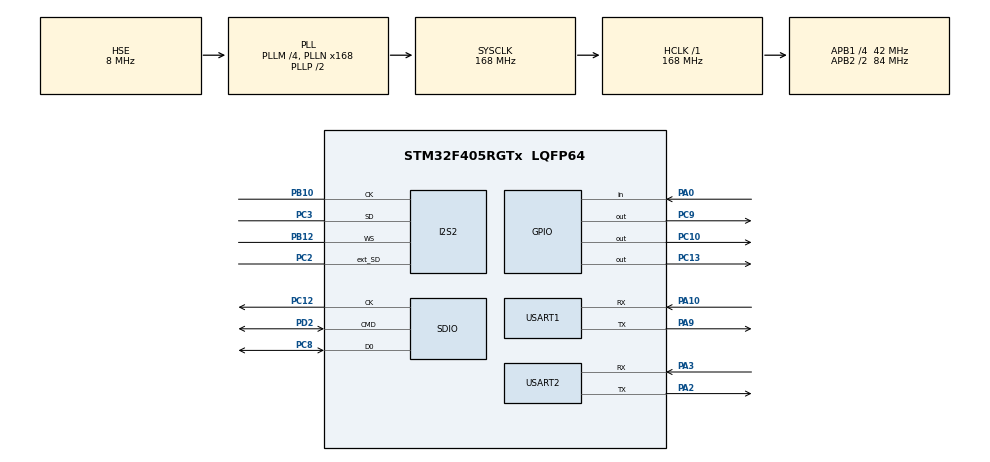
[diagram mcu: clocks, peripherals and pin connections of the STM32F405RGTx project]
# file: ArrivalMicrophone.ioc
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Mcu.Family=STM32F4
PC3.Mode=Full_Duplex_Master
Dma.SPI2_RX.0.Instance=DMA1_Stream3
PH0-OSC_IN.Signal=RCC_OSC_IN
RCC.CortexFreq_Value=168000000
Dma.SDIO_RX.1.PeriphDataAlignment=DMA_PDATAALIGN_WORD
PB10.GPIO_Speed=GPIO_SPEED_FREQ_VERY_HIGH
PB10.Mode=Full_Duplex_Master
VP_FATFS_VS_SDIO.Mode=SDIO
PA10.GPIO_PuPd=GPIO_PULLUP
PC10.Signal=GPIO_Output
PC12.Signal=SDIO_CK
Dma.SDIO_RX.1.Mode=DMA_PFCTRL
PA3.GPIO_PuPd=GPIO_PULLUP
Dma.SDIO_RX.1.Direction=DMA_PERIPH_TO_MEMORY
Dma.SDIO_RX.1.Priority=DMA_PRIORITY_LOW
FREERTOS.configTICK_RATE_HZ=100
PC2.GPIO_Speed=GPIO_SPEED_FREQ_VERY_HIGH
PC3.GPIO_Speed=GPIO_SPEED_FREQ_VERY_HIGH
RCC.SYSCLKSource=RCC_SYSCLKSOURCE_PLLCLK
ProjectManager.StackSize=0x400
VP_FREERTOS_VS_CMSIS_V2.Mode=CMSIS_V2
Dma.SDIO_RX.1.Instance=DMA2_Stream3
Dma.SDIO_TX.2.Mode=DMA_PFCTRL
Dma.SDIO_TX.2.MemDataAlignment=DMA_MDATAALIGN_WORD
RCC.HCLKFreq_Value=168000000
RCC.APB2TimFreq_Value=168000000
Dma.SDIO_RX.1.FIFOMode=DMA_FIFOMODE_ENABLE
FATFS._MULTI_PARTITION=1
PC3.Signal=I2S2_SD
RCC.AHBFreq_Value=168000000
PH0-OSC_IN.Mode=HSE-External-Oscillator
RCC.HSE_VALUE=8000000
PC13-ANTI_TAMP.Signal=GPIO_Output
VP_SYS_VS_tim1.Mode=TIM1
Dma.SDIO_TX.2.Direction=DMA_MEMORY_TO_PERIPH
Dma.SPI2_RX.0.MemDataAlignment=DMA_MDATAALIGN_HALFWORD
I2S2.DataFormat=I2S_DATAFORMAT_24B
PC10.PinState=GPIO_PIN_SET
Dma.SPI2_RX.0.MemInc=DMA_MINC_ENABLE
PH1-OSC_OUT.Mode=HSE-External-Oscillator
Mcu.Package=LQFP64
PB12.Mode=Full_Duplex_Master
NVIC.TimeBase=TIM1_UP_TIM10_IRQn
USART2.VirtualMode=VM_ASYNC
Dma.SDIO_TX.2.PeriphBurst=DMA_PBURST_INC4
I2S2.Mode=I2S_MODE_MASTER_RX
NVIC.TimeBaseIP=TIM1
PA10.Signal=USART1_RX
Dma.SDIO_RX.1.PeriphBurst=DMA_PBURST_INC4
RCC.APB2CLKDivider=RCC_HCLK_DIV2
Dma.Request2=SDIO_TX
Dma.Request1=SDIO_RX
RCC.APB1TimFreq_Value=84000000
Dma.SPI2_RX.0.Direction=DMA_PERIPH_TO_MEMORY
Dma.Request0=SPI2_RX
Dma.SDIO_TX.2.FIFOThreshold=DMA_FIFO_THRESHOLD_FULL
PA3.Signal=USART2_RX
RCC.PLLSourceVirtual=RCC_PLLSOURCE_HSE
Dma.SDIO_TX.2.MemInc=DMA_MINC_ENABLE
I2S2.AudioFreq=I2S_AUDIOFREQ_16K
FREERTOS.Tasks01=mainTask,24,1024,mainTask_main,Default,&mainTask,Static,defaultTaskBuffer,defaultTaskControlBlock
I2S2.Instance=SPI$Index
PA10.Mode=Asynchronous
Dma.SPI2_RX.0.Mode=DMA_CIRCULAR
PC8.Signal=SDIO_D0
PC2.Signal=I2S2_ext_SD
PC9.PinState=GPIO_PIN_SET
PC2.Mode=Full_Duplex_Master
Dma.SDIO_TX.2.Instance=DMA2_Stream6
RCC.APB1CLKDivider=RCC_HCLK_DIV4
NVIC.USART2_IRQn=true\:0\:0\:false\:false\:true\:true\:true\:true
NVIC.SDIO_IRQn=true\:0\:0\:false\:false\:true\:false\:true\:true
PC13-ANTI_TAMP.PinState=GPIO_PIN_SET
PA0-WKUP.Signal=GPIO_Input
Dma.SDIO_RX.1.PeriphInc=DMA_PINC_DISABLE
PA3.Mode=Asynchronous
PA9.Mode=Asynchronous
Dma.SPI2_RX.0.PeriphDataAlignment=DMA_PDATAALIGN_HALFWORD
ProjectManager.TargetToolchain=Makefile
PA9.Signal=USART1_TX
I2S2.VirtualMode=I2S_MODE_MASTER
Dma.SDIO_TX.2.PeriphDataAlignment=DMA_PDATAALIGN_WORD
SDIO.ClockDiv=3
NVIC.DMA2_Stream3_IRQn=true\:0\:0\:false\:false\:true\:true\:false\:true
NVIC.DMA2_Stream6_IRQn=true\:0\:0\:false\:false\:true\:true\:false\:true
RCC.LSE_VALUE=32768
PB12.GPIO_Speed=GPIO_SPEED_FREQ_VERY_HIGH
Dma.SDIO_RX.1.MemDataAlignment=DMA_MDATAALIGN_WORD
PB10.Signal=I2S2_CK
Dma.SDIO_RX.1.FIFOThreshold=DMA_FIFO_THRESHOLD_FULL
PD2.Mode=SD_1_bit
PC12.Mode=SD_1_bit
board=custom
Dma.SDIO_RX.1.MemBurst=DMA_MBURST_INC4
RCC.VCOOutputFreq_Value=336000000
RCC.APB2Freq_Value=84000000
PH1-OSC_OUT.Signal=RCC_OSC_OUT
Dma.SPI2_RX.0.FIFOMode=DMA_FIFOMODE_DISABLE
PC2.GPIO_PuPd=GPIO_PULLUP
Dma.SPI2_RX.0.Priority=DMA_PRIORITY_HIGH
Mcu.Name=STM32F405RGTx
PA2.Signal=USART2_TX
Dma.SDIO_TX.2.Priority=DMA_PRIORITY_LOW
FATFS._MAX_SS=4096
I2S2.FullDuplexMode=I2S_FULLDUPLEXMODE_ENABLE
PC8.Mode=SD_1_bit
RCC.48MHZClocksFreq_Value=48000000
RCC.SYSCLKFreq_VALUE=168000000
I2S2.ErrorAudioFreq=-0.26 %
Dma.SPI2_RX.0.PeriphInc=DMA_PINC_DISABLE
USART1.VirtualMode=VM_ASYNC
Dma.SDIO_TX.2.MemBurst=DMA_MBURST_INC4
ProjectManager.HeapSize=0x200
Dma.SDIO_RX.1.MemInc=DMA_MINC_ENABLE
Dma.SDIO_TX.2.FIFOMode=DMA_FIFOMODE_ENABLE
NVIC.TIM1_UP_TIM10_IRQn=true\:0\:0\:false\:false\:true\:false\:true\:true
RCC.HSI_VALUE=16000000
RCC.PLLQ=7
NVIC.PriorityGroup=NVIC_PRIORITYGROUP_4
RCC.PLLM=4
RCC.PLLN=168
PA2.Mode=Asynchronous
Dma.SDIO_TX.2.PeriphInc=DMA_PINC_DISABLE
PA0-WKUP.GPIO_PuPd=GPIO_PULLUP
NVIC.DMA1_Stream3_IRQn=true\:0\:0\:false\:false\:true\:true\:false\:true
PC9.Signal=GPIO_Output
PD2.Signal=SDIO_CMD
RCC.APB1Freq_Value=42000000
I2S2.RealAudioFreq=15.957 KHz
PB12.Signal=I2S2_WS
PC3.GPIO_PuPd=GPIO_PULLUP

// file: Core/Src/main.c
/* USER CODE BEGIN Header */
/**
  ******************************************************************************
  * @file           : main.c
  * @brief          : Main program body
  ******************************************************************************
  * @attention
  *
  * <h2><center>&copy; Copyright (c) 2020 STMicroelectronics.
  * All rights reserved.</center></h2>
  *
  * This software component is licensed by ST under Ultimate Liberty license
  * SLA0044, the "License"; You may not use this file except in compliance with
  * the License. You may obtain a copy of the License at:
  *                             www.st.com/SLA0044
  *
  ******************************************************************************
  */
/* USER CODE END Header */
#include "main.h"
#include "cmsis_os.h"
#include "fatfs.h"

/* USER CODE BEGIN Includes */
#include "../../src/maintask.h"
#include "../../src/led.h"
/* USER CODE END Includes */

typedef StaticTask_t osStaticThreadDef_t;

I2S_HandleTypeDef hi2s2;
DMA_HandleTypeDef hdma_spi2_rx;

SD_HandleTypeDef hsd;
DMA_HandleTypeDef hdma_sdio_rx;
DMA_HandleTypeDef hdma_sdio_tx;

UART_HandleTypeDef huart1;
UART_HandleTypeDef huart2;

/* Definitions for mainTask */
osThreadId_t mainTaskHandle;
uint32_t defaultTaskBuffer[ 1024 ];
osStaticThreadDef_t defaultTaskControlBlock;
const osThreadAttr_t mainTask_attributes = {
  .name = "mainTask",
  .stack_mem = &defaultTaskBuffer[0],
  .stack_size = sizeof(defaultTaskBuffer),
  .cb_mem = &defaultTaskControlBlock,
  .cb_size = sizeof(defaultTaskControlBlock),
  .priority = (osPriority_t) osPriorityNormal,
};

void SystemClock_Config(void);
static void MX_GPIO_Init(void);
static void MX_DMA_Init(void);
static void MX_I2S2_Init(void);
static void MX_SDIO_SD_Init(void);
static void MX_USART1_UART_Init(void);
static void MX_USART2_UART_Init(void);
void mainTask_main(void *argument);

int main(void)
{

  /* MCU Configuration--------------------------------------------------------*/

  /* Reset of all peripherals, Initializes the Flash interface and the Systick. */
  HAL_Init();

  /* Configure the system clock */
  SystemClock_Config();

  /* Initialize all configured peripherals */
  MX_GPIO_Init();
  MX_DMA_Init();
  MX_I2S2_Init();
  MX_SDIO_SD_Init();
  MX_USART1_UART_Init();
  MX_USART2_UART_Init();
  MX_FATFS_Init();

  /* Init scheduler */
  osKernelInitialize();

  /* Create the thread(s) */
  /* creation of mainTask */
  mainTaskHandle = osThreadNew(mainTask_main, (void*) &mainTask, &mainTask_attributes);

  /* Start scheduler */
  osKernelStart();

  /* We should never get here as control is now taken by the scheduler */
  /* Infinite loop */
  while (1)
  {

  }
}

void SystemClock_Config(void)
{
  RCC_OscInitTypeDef RCC_OscInitStruct = {0};
  RCC_ClkInitTypeDef RCC_ClkInitStruct = {0};
  RCC_PeriphCLKInitTypeDef PeriphClkInitStruct = {0};

  /** Configure the main internal regulator output voltage
  */
  __HAL_RCC_PWR_CLK_ENABLE();
  __HAL_PWR_VOLTAGESCALING_CONFIG(PWR_REGULATOR_VOLTAGE_SCALE1);
  /** Initializes the RCC Oscillators according to the specified parameters
  * in the RCC_OscInitTypeDef structure.
  */
  RCC_OscInitStruct.OscillatorType = RCC_OSCILLATORTYPE_HSE;
  RCC_OscInitStruct.HSEState = RCC_HSE_ON;
  RCC_OscInitStruct.PLL.PLLState = RCC_PLL_ON;
  RCC_OscInitStruct.PLL.PLLSource = RCC_PLLSOURCE_HSE;
  RCC_OscInitStruct.PLL.PLLM = 4;
  RCC_OscInitStruct.PLL.PLLN = 168;
  RCC_OscInitStruct.PLL.PLLP = RCC_PLLP_DIV2;
  RCC_OscInitStruct.PLL.PLLQ = 7;
  if (HAL_RCC_OscConfig(&RCC_OscInitStruct) != HAL_OK)
  {
    Error_Handler();
  }
  /** Initializes the CPU, AHB and APB buses clocks
  */
  RCC_ClkInitStruct.ClockType = RCC_CLOCKTYPE_HCLK|RCC_CLOCKTYPE_SYSCLK
                              |RCC_CLOCKTYPE_PCLK1|RCC_CLOCKTYPE_PCLK2;
  RCC_ClkInitStruct.SYSCLKSource = RCC_SYSCLKSOURCE_PLLCLK;
  RCC_ClkInitStruct.AHBCLKDivider = RCC_SYSCLK_DIV1;
  RCC_ClkInitStruct.APB1CLKDivider = RCC_HCLK_DIV4;
  RCC_ClkInitStruct.APB2CLKDivider = RCC_HCLK_DIV2;

  if (HAL_RCC_ClockConfig(&RCC_ClkInitStruct, FLASH_LATENCY_5) != HAL_OK)
  {
    Error_Handler();
  }
  PeriphClkInitStruct.PeriphClockSelection = RCC_PERIPHCLK_I2S;
  PeriphClkInitStruct.PLLI2S.PLLI2SN = 192;
  PeriphClkInitStruct.PLLI2S.PLLI2SR = 2;
  if (HAL_RCCEx_PeriphCLKConfig(&PeriphClkInitStruct) != HAL_OK)
  {
    Error_Handler();
  }
}

static void MX_I2S2_Init(void)
{

  hi2s2.Instance = SPI2;
  hi2s2.Init.Mode = I2S_MODE_MASTER_RX;
  hi2s2.Init.Standard = I2S_STANDARD_PHILIPS;
  hi2s2.Init.DataFormat = I2S_DATAFORMAT_24B;
  hi2s2.Init.MCLKOutput = I2S_MCLKOUTPUT_DISABLE;
  hi2s2.Init.AudioFreq = I2S_AUDIOFREQ_16K;
  hi2s2.Init.CPOL = I2S_CPOL_LOW;
  hi2s2.Init.ClockSource = I2S_CLOCK_PLL;
  hi2s2.Init.FullDuplexMode = I2S_FULLDUPLEXMODE_ENABLE;
  if (HAL_I2S_Init(&hi2s2) != HAL_OK)
  {
    Error_Handler();
  }

}

static void MX_SDIO_SD_Init(void)
{

  hsd.Instance = SDIO;
  hsd.Init.ClockEdge = SDIO_CLOCK_EDGE_RISING;
  hsd.Init.ClockBypass = SDIO_CLOCK_BYPASS_DISABLE;
  hsd.Init.ClockPowerSave = SDIO_CLOCK_POWER_SAVE_DISABLE;
  hsd.Init.BusWide = SDIO_BUS_WIDE_1B;
  hsd.Init.HardwareFlowControl = SDIO_HARDWARE_FLOW_CONTROL_DISABLE;
  hsd.Init.ClockDiv = 3;

}

static void MX_USART1_UART_Init(void)
{

  huart1.Instance = USART1;
  huart1.Init.BaudRate = 115200;
  huart1.Init.WordLength = UART_WORDLENGTH_8B;
  huart1.Init.StopBits = UART_STOPBITS_1;
  huart1.Init.Parity = UART_PARITY_NONE;
  huart1.Init.Mode = UART_MODE_TX_RX;
  huart1.Init.HwFlowCtl = UART_HWCONTROL_NONE;
  huart1.Init.OverSampling = UART_OVERSAMPLING_16;
  if (HAL_UART_Init(&huart1) != HAL_OK)
  {
    Error_Handler();
  }

}

static void MX_USART2_UART_Init(void)
{

  huart2.Instance = USART2;
  huart2.Init.BaudRate = 115200;
  huart2.Init.WordLength = UART_WORDLENGTH_8B;
  huart2.Init.StopBits = UART_STOPBITS_1;
  huart2.Init.Parity = UART_PARITY_NONE;
  huart2.Init.Mode = UART_MODE_TX_RX;
  huart2.Init.HwFlowCtl = UART_HWCONTROL_NONE;
  huart2.Init.OverSampling = UART_OVERSAMPLING_16;
  if (HAL_UART_Init(&huart2) != HAL_OK)
  {
    Error_Handler();
  }

}

static void MX_DMA_Init(void)
{

  /* DMA controller clock enable */
  __HAL_RCC_DMA1_CLK_ENABLE();
  __HAL_RCC_DMA2_CLK_ENABLE();

  /* DMA interrupt init */
  /* DMA1_Stream3_IRQn interrupt configuration */
  HAL_NVIC_SetPriority(DMA1_Stream3_IRQn, 0, 0);
  HAL_NVIC_EnableIRQ(DMA1_Stream3_IRQn);
  /* DMA2_Stream3_IRQn interrupt configuration */
  HAL_NVIC_SetPriority(DMA2_Stream3_IRQn, 0, 0);
  HAL_NVIC_EnableIRQ(DMA2_Stream3_IRQn);
  /* DMA2_Stream6_IRQn interrupt configuration */
  HAL_NVIC_SetPriority(DMA2_Stream6_IRQn, 0, 0);
  HAL_NVIC_EnableIRQ(DMA2_Stream6_IRQn);

}

static void MX_GPIO_Init(void)
{
  GPIO_InitTypeDef GPIO_InitStruct = {0};

  /* GPIO Ports Clock Enable */
  __HAL_RCC_GPIOC_CLK_ENABLE();
  __HAL_RCC_GPIOH_CLK_ENABLE();
  __HAL_RCC_GPIOA_CLK_ENABLE();
  __HAL_RCC_GPIOB_CLK_ENABLE();
  __HAL_RCC_GPIOD_CLK_ENABLE();

  /*Configure GPIO pin Output Level */
  HAL_GPIO_WritePin(GPIOC, GPIO_PIN_13|GPIO_PIN_9|GPIO_PIN_10, GPIO_PIN_SET);

  /*Configure GPIO pins : PC13 PC9 PC10 */
  GPIO_InitStruct.Pin = GPIO_PIN_13|GPIO_PIN_9|GPIO_PIN_10;
  GPIO_InitStruct.Mode = GPIO_MODE_OUTPUT_PP;
  GPIO_InitStruct.Pull = GPIO_NOPULL;
  GPIO_InitStruct.Speed = GPIO_SPEED_FREQ_LOW;
  HAL_GPIO_Init(GPIOC, &GPIO_InitStruct);

  /*Configure GPIO pin : PA0 */
  GPIO_InitStruct.Pin = GPIO_PIN_0;
  GPIO_InitStruct.Mode = GPIO_MODE_INPUT;
  GPIO_InitStruct.Pull = GPIO_PULLUP;
  HAL_GPIO_Init(GPIOA, &GPIO_InitStruct);

}

/* USER CODE BEGIN 4 */
#define mainTask_main mainTask_main_unused
/* USER CODE END 4 */

void mainTask_main(void *argument)
{
  for(;;)
  {
    osDelay(1);
  }
}

void HAL_TIM_PeriodElapsedCallback(TIM_HandleTypeDef *htim)
{
  if (htim->Instance == TIM1) {
    HAL_IncTick();
  }
}

void Error_Handler(void)
{
  /* USER CODE BEGIN Error_Handler_Debug */
  /* User can add his own implementation to report the HAL error return state */
    ledSet(ledRed | ledGreen | ledBlue);
    __disable_irq ();
    for(;;)
    {
    }
  /* USER CODE END Error_Handler_Debug */
}

/************************ (C) COPYRIGHT STMicroelectronics *****END OF FILE****/
